# ATmega162 register map
Vendor: Atmel; File version: 1.0
CPU: other r0p0, little endian, no MPU, no FPU, 4 interrupt priority bits
Registers are 8-bit, read-write, reset 0x0 unless marked. A register's access mark holds for its fields unless they carry their own. Offsets are from the block's base; [hi:lo] are bit positions; 'fields as' and 'values as' point back to an identical list.

## EEPROM
Base 0x0080003C
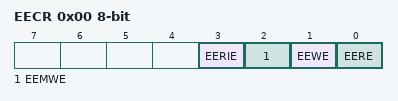
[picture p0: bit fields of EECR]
0x00 EECR — EEPROM Control Register
  [3] EERIE — EEPROM Ready Interrupt Enable
  [2] EEMWE — EEPROM Master Write Enable
  [1] EEWE — EEPROM Write Enable
  [0] EERE — EEPROM Read Enable
0x01 EEDR — EEPROM Data Register
  [7:0] EEDR — EEPROM Data Register bits
0x02 EEAR 16-bit (reset mask 0xFF) — EEPROM Address Register Bytes
  [8:0] EEAR — EEPROM Address Register bits

## EXINT — External Interrupts
Base 0x00800055
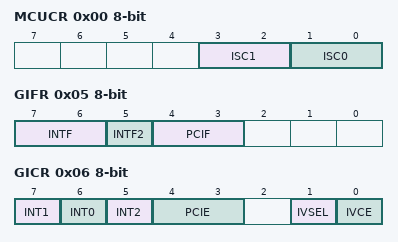
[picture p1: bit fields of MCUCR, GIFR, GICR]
0x00 MCUCR — MCU Control Register
  [3:2] ISC1 — Interrupt Sense Control 1 Bits
    0=LOW_LEVEL_OF_INTX; 1=ANY_LOGICAL_CHANGE_OF_INTX; 2=FALLING_EDGE_OF_INTX; 3=RISING_EDGE_OF_INTX
  [1:0] ISC0 — Interrupt Sense Control 0 Bits
    values as ISC1
0x01 EMCUCR — Extended MCU Control Register
  [0] ISC2 — Interrupt Sense Control 2
0x05 GIFR — General Interrupt Flag Register (read-only for debugger)
  [7:6] INTF — External Interrupt Flags
  [5] INTF2 — External Interrupt Flag 2
  [4:3] PCIF — Pin Change Interrupt Flags
0x06 GICR — General Interrupt Control Register
  [7] INT1 — External Interrupt Request 1 Enable
  [6] INT0 — External Interrupt Request 0 Enable
  [5] INT2 — External Interrupt Request 2 Enable
  [4:3] PCIE — Pin Change Interrupt Enables
  [1] IVSEL — Interrupt Vector Select
  [0] IVCE — Interrupt Vector Change Enable
0x16 PCMSK0 — Pin Change Enable Mask
  [7:0] PCINT — Pin Change Interrupt mask bits
0x17 PCMSK1 — Pin Change Mask Register 1
  [7:0] PCINT — Pin Change Interrupt mask bits

## JTAG — JTAG Interface
Base 0x00800024
0x00 OCDR — On-Chip Debug Related Register in I/O Memory (write-only for debugger)
  [7:0] OCDR — On-Chip Debug Register Bits
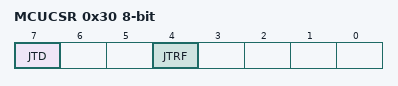
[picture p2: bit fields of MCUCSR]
0x30 MCUCSR — MCU Control And Status Register
  [7] JTD — JTAG Interface Disable
  [4] JTRF — JTAG Reset Flag

## PORTA — I/O Port
Base 0x00800039
0x00 PINA — Port A Input Pins (read-only for debugger)
0x01 DDRA — Port A Data Direction Register
0x02 PORTA — Port A Data Register

## PORTB — I/O Port
Base 0x00800036
0x00 PINB — Port B Input Pins (read-only for debugger)
0x01 DDRB — Port B Data Direction Register
0x02 PORTB — Port B Data Register

## PORTC — I/O Port
Base 0x00800033
0x00 PINC — Port C Input Pins (read-only for debugger)
0x01 DDRC — Port C Data Direction Register
0x02 PORTC — Port C Data Register

## PORTD — I/O Port
Base 0x00800030
0x00 PIND — Port D Input Pins (read-only for debugger)
0x01 DDRD — Port D Data Direction Register
0x02 PORTD — Port D Data Register

## PORTE — I/O Port
Base 0x00800025
0x00 PINE — Input Pins, Port E (read-only for debugger)
0x01 DDRE — Data Direction Register, Port E
0x02 PORTE — Data Register, Port E

## SPI — Serial Peripheral Interface
Base 0x0080002D
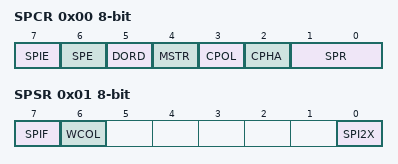
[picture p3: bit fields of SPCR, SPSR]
0x00 SPCR — SPI Control Register
  [7] SPIE — SPI Interrupt Enable
  [6] SPE — SPI Enable
  [5] DORD — Data Order
  [4] MSTR — Master/Slave Select
  [3] CPOL — Clock polarity
  [2] CPHA — Clock Phase
  [1:0] SPR — SPI Clock Rate Selects
    0=FOSC_4; 1=FOSC_16; 3=FOSC_128
0x01 SPSR — SPI Status Register (read-only for debugger)
  [7] SPIF — SPI Interrupt Flag
  [6] WCOL — Write Collision Flag
  [0] SPI2X — Double SPI Speed Bit
0x02 SPDR — SPI Data Register (write-only for debugger)

## TC0 — Timer/Counter, 8-bit
Base 0x00800051
0x00 OCR0 — Timer/Counter 0 Output Compare Register
0x01 TCNT0 — Timer/Counter 0 Register
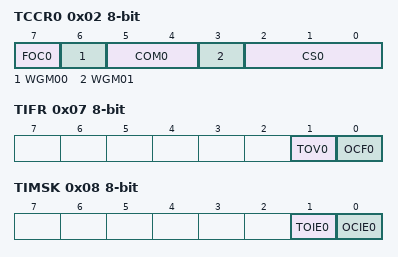
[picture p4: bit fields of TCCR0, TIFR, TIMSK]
0x02 TCCR0 — Timer/Counter 0 Control Register
  [7] FOC0 — Force Output Compare
  [6] WGM00 — Waveform Generation Mode 0
    0=NORMAL; 1=CTC
  [5:4] COM0 — Compare Match Output Modes
  [3] WGM01 — Waveform Generation Mode 1
  [2:0] CS0 — Clock Selects
    0=NO_CLOCK_SOURCE_STOPPED; 1=RUNNING_NO_PRESCALING; 2=RUNNING_CLK_8; 3=RUNNING_CLK_64; 4=RUNNING_CLK_256; 5=RUNNING_CLK_1024; 6=RUNNING_EXTCLK_TN_FALLING_EDGE; 7=RUNNING_EXTCLK_TN_RISING_EDGE
0x07 TIFR — Timer/Counter Interrupt Flag register (read-only for debugger)
  [1] TOV0 — Timer/Counter0 Overflow Flag
  [0] OCF0 — Output Compare Flag 0
0x08 TIMSK — Timer/Counter Interrupt Mask Register
  [1] TOIE0 — Timer/Counter0 Overflow Interrupt Enable
  [0] OCIE0 — Timer/Counter0 Output Compare Match Interrupt register
